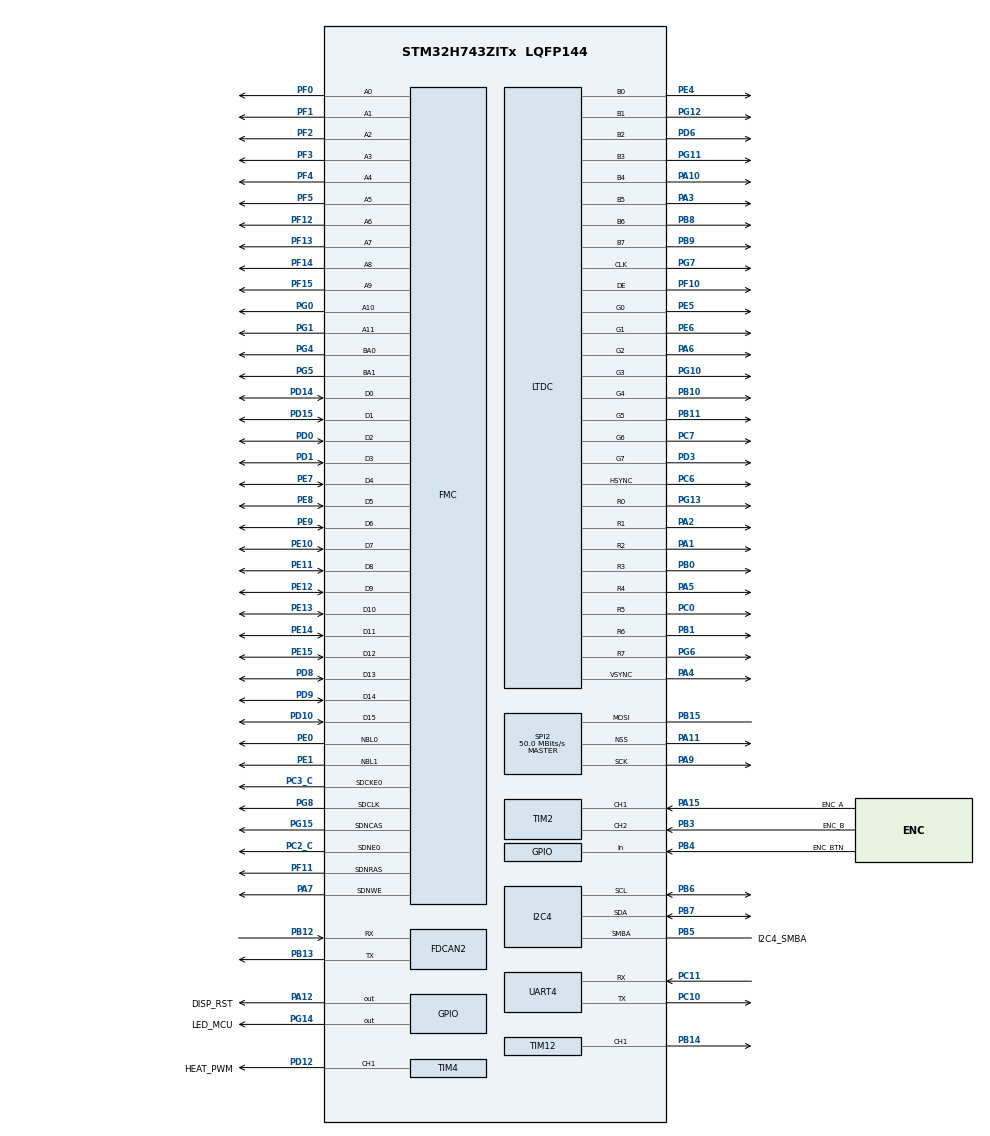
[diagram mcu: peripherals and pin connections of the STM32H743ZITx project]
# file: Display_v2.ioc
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CORTEX_M7.AccessPermission-Cortex_Memory_Protection_Unit_Region0_Settings=MPU_REGION_PRIV_RW
CORTEX_M7.AccessPermission-Cortex_Memory_Protection_Unit_Region1_Settings=MPU_REGION_PRIV_RO
CORTEX_M7.AccessPermission-Cortex_Memory_Protection_Unit_Region2_Settings=MPU_REGION_PRIV_RW
CORTEX_M7.AccessPermission-Cortex_Memory_Protection_Unit_Region3_Settings=MPU_REGION_PRIV_RW
CORTEX_M7.AccessPermission-Cortex_Memory_Protection_Unit_Region4_Settings=MPU_REGION_PRIV_RW
CORTEX_M7.AccessPermission-Cortex_Memory_Protection_Unit_Region5_Settings=MPU_REGION_PRIV_RW
CORTEX_M7.AccessPermission-Cortex_Memory_Protection_Unit_Region6_Settings=MPU_REGION_PRIV_RW
CORTEX_M7.AccessPermission-Cortex_Memory_Protection_Unit_Region7_Settings=MPU_REGION_PRIV_RW
CORTEX_M7.AccessPermission-Cortex_Memory_Protection_Unit_Region8_Settings=MPU_REGION_PRIV_RW
CORTEX_M7.BaseAddress-Cortex_Memory_Protection_Unit_Region1_Settings=0x08000000
CORTEX_M7.BaseAddress-Cortex_Memory_Protection_Unit_Region2_Settings=0x20000000
CORTEX_M7.BaseAddress-Cortex_Memory_Protection_Unit_Region3_Settings=0x24000000
CORTEX_M7.BaseAddress-Cortex_Memory_Protection_Unit_Region4_Settings=0x30000000
CORTEX_M7.BaseAddress-Cortex_Memory_Protection_Unit_Region5_Settings=0x38000000
CORTEX_M7.BaseAddress-Cortex_Memory_Protection_Unit_Region6_Settings=0x40000000
CORTEX_M7.BaseAddress-Cortex_Memory_Protection_Unit_Region7_Settings=0x60000000
CORTEX_M7.BaseAddress-Cortex_Memory_Protection_Unit_Region8_Settings=0x60000000
CORTEX_M7.CPU_DCache=Enabled
CORTEX_M7.CPU_ICache=Enabled
CORTEX_M7.DisableExec-Cortex_Memory_Protection_Unit_Region2_Settings=MPU_INSTRUCTION_ACCESS_DISABLE
CORTEX_M7.DisableExec-Cortex_Memory_Protection_Unit_Region3_Settings=MPU_INSTRUCTION_ACCESS_DISABLE
CORTEX_M7.DisableExec-Cortex_Memory_Protection_Unit_Region4_Settings=MPU_INSTRUCTION_ACCESS_DISABLE
CORTEX_M7.DisableExec-Cortex_Memory_Protection_Unit_Region5_Settings=MPU_INSTRUCTION_ACCESS_DISABLE
CORTEX_M7.DisableExec-Cortex_Memory_Protection_Unit_Region6_Settings=MPU_INSTRUCTION_ACCESS_DISABLE
CORTEX_M7.DisableExec-Cortex_Memory_Protection_Unit_Region7_Settings=MPU_INSTRUCTION_ACCESS_DISABLE
CORTEX_M7.DisableExec-Cortex_Memory_Protection_Unit_Region8_Settings=MPU_INSTRUCTION_ACCESS_DISABLE
CORTEX_M7.Enable-Cortex_Memory_Protection_Unit_Region0_Settings=MPU_REGION_ENABLE
CORTEX_M7.Enable-Cortex_Memory_Protection_Unit_Region1_Settings=MPU_REGION_ENABLE
CORTEX_M7.Enable-Cortex_Memory_Protection_Unit_Region2_Settings=MPU_REGION_ENABLE
CORTEX_M7.Enable-Cortex_Memory_Protection_Unit_Region3_Settings=MPU_REGION_ENABLE
CORTEX_M7.Enable-Cortex_Memory_Protection_Unit_Region4_Settings=MPU_REGION_ENABLE
CORTEX_M7.Enable-Cortex_Memory_Protection_Unit_Region5_Settings=MPU_REGION_ENABLE
CORTEX_M7.Enable-Cortex_Memory_Protection_Unit_Region6_Settings=MPU_REGION_ENABLE
CORTEX_M7.Enable-Cortex_Memory_Protection_Unit_Region7_Settings=MPU_REGION_ENABLE
CORTEX_M7.Enable-Cortex_Memory_Protection_Unit_Region8_Settings=MPU_REGION_ENABLE
CORTEX_M7.IsBufferable-Cortex_Memory_Protection_Unit_Region0_Settings=MPU_ACCESS_NOT_BUFFERABLE
CORTEX_M7.IsBufferable-Cortex_Memory_Protection_Unit_Region1_Settings=MPU_ACCESS_BUFFERABLE
CORTEX_M7.IsBufferable-Cortex_Memory_Protection_Unit_Region2_Settings=MPU_ACCESS_BUFFERABLE
CORTEX_M7.IsBufferable-Cortex_Memory_Protection_Unit_Region3_Settings=MPU_ACCESS_BUFFERABLE
CORTEX_M7.IsBufferable-Cortex_Memory_Protection_Unit_Region4_Settings=MPU_ACCESS_BUFFERABLE
CORTEX_M7.IsBufferable-Cortex_Memory_Protection_Unit_Region5_Settings=MPU_ACCESS_BUFFERABLE
CORTEX_M7.IsBufferable-Cortex_Memory_Protection_Unit_Region6_Settings=MPU_ACCESS_NOT_BUFFERABLE
CORTEX_M7.IsBufferable-Cortex_Memory_Protection_Unit_Region7_Settings=MPU_ACCESS_BUFFERABLE
CORTEX_M7.IsBufferable-Cortex_Memory_Protection_Unit_Region8_Settings=MPU_ACCESS_BUFFERABLE
CORTEX_M7.IsCacheable-Cortex_Memory_Protection_Unit_Region0_Settings=MPU_ACCESS_NOT_CACHEABLE
CORTEX_M7.IsCacheable-Cortex_Memory_Protection_Unit_Region1_Settings=MPU_ACCESS_CACHEABLE
CORTEX_M7.IsCacheable-Cortex_Memory_Protection_Unit_Region2_Settings=MPU_ACCESS_CACHEABLE
CORTEX_M7.IsCacheable-Cortex_Memory_Protection_Unit_Region3_Settings=MPU_ACCESS_CACHEABLE
CORTEX_M7.IsCacheable-Cortex_Memory_Protection_Unit_Region4_Settings=MPU_ACCESS_CACHEABLE
CORTEX_M7.IsCacheable-Cortex_Memory_Protection_Unit_Region5_Settings=MPU_ACCESS_CACHEABLE
CORTEX_M7.IsCacheable-Cortex_Memory_Protection_Unit_Region6_Settings=MPU_ACCESS_NOT_CACHEABLE
CORTEX_M7.IsCacheable-Cortex_Memory_Protection_Unit_Region7_Settings=MPU_ACCESS_CACHEABLE
CORTEX_M7.IsCacheable-Cortex_Memory_Protection_Unit_Region8_Settings=MPU_ACCESS_CACHEABLE
CORTEX_M7.IsShareable-Cortex_Memory_Protection_Unit_Region5_Settings=MPU_ACCESS_NOT_SHAREABLE
CORTEX_M7.IsShareable-Cortex_Memory_Protection_Unit_Region7_Settings=MPU_ACCESS_NOT_SHAREABLE
CORTEX_M7.IsShareable-Cortex_Memory_Protection_Unit_Region8_Settings=MPU_ACCESS_SHAREABLE
CORTEX_M7.MPU_Control=MPU_HARDFAULT_NMI
CORTEX_M7.Size-Cortex_Memory_Protection_Unit_Region0_Settings=MPU_REGION_SIZE_64KB
CORTEX_M7.Size-Cortex_Memory_Protection_Unit_Region1_Settings=MPU_REGION_SIZE_2MB
CORTEX_M7.Size-Cortex_Memory_Protection_Unit_Region2_Settings=MPU_REGION_SIZE_128KB
CORTEX_M7.Size-Cortex_Memory_Protection_Unit_Region3_Settings=MPU_REGION_SIZE_512KB
CORTEX_M7.Size-Cortex_Memory_Protection_Unit_Region4_Settings=MPU_REGION_SIZE_512KB
CORTEX_M7.Size-Cortex_Memory_Protection_Unit_Region5_Settings=MPU_REGION_SIZE_64KB
CORTEX_M7.Size-Cortex_Memory_Protection_Unit_Region6_Settings=MPU_REGION_SIZE_512MB
CORTEX_M7.Size-Cortex_Memory_Protection_Unit_Region7_Settings=MPU_REGION_SIZE_8MB
CORTEX_M7.Size-Cortex_Memory_Protection_Unit_Region8_Settings=MPU_REGION_SIZE_1MB
CORTEX_M7.SubRegionDisable-Cortex_Memory_Protection_Unit_Region5_Settings=0x00
CORTEX_M7.TypeExtField-Cortex_Memory_Protection_Unit_Region3_Settings=MPU_TEX_LEVEL0
CORTEX_M7.TypeExtField-Cortex_Memory_Protection_Unit_Region4_Settings=MPU_TEX_LEVEL0
CORTEX_M7.TypeExtField-Cortex_Memory_Protection_Unit_Region5_Settings=MPU_TEX_LEVEL0
CORTEX_M7.TypeExtField-Cortex_Memory_Protection_Unit_Region7_Settings=MPU_TEX_LEVEL0
CORTEX_M7.default_mode_Activation=0
FDCAN2.AutoRetransmission=DISABLE
FDCAN2.CalculateBaudRateNominal=400000
FDCAN2.CalculateTimeBitNominal=2500
FDCAN2.CalculateTimeQuantumNominal=100.0
FDCAN2.ClockCalibrationCCU=DISABLE
FDCAN2.DataPrescaler=10
FDCAN2.DataTimeSeg1=18
FDCAN2.DataTimeSeg2=6
FDCAN2.ExtFiltersNbr=12
FDCAN2.FrameFormat=FDCAN_FRAME_CLASSIC
FDCAN2.NominalPrescaler=10
FDCAN2.NominalTimeSeg1=18
FDCAN2.NominalTimeSeg2=6
FDCAN2.ProtocolException=DISABLE
FDCAN2.RxBuffersNbr=12
FDCAN2.RxFifo0ElmtsNbr=0
FDCAN2.RxFifo1ElmtsNbr=0
FDCAN2.StdFiltersNbr=0
FDCAN2.TxFifoQueueElmtsNbr=32
FMC.BankMapConfig=FMC_SWAPBMAP_SDRAM_SRAM
FMC.CASLatency1=FMC_SDRAM_CAS_LATENCY_3
FMC.ExitSelfRefreshDelay1=14
FMC.LoadToActiveDelay1=2
FMC.RCDDelay1=3
FMC.RPDelay1=3
FMC.RPDelay2=3
FMC.ReadBurst1=FMC_SDRAM_RBURST_ENABLE
FMC.ReadBurst2=FMC_SDRAM_RBURST_ENABLE
FMC.RowCycleDelay1=12
FMC.RowCycleDelay2=12
FMC.SDClockPeriod1=FMC_SDRAM_CLOCK_PERIOD_2
FMC.SDClockPeriod2=FMC_SDRAM_CLOCK_PERIOD_2
FMC.SelfRefreshTime1=8
FMC.WriteRecoveryTime1=3
I2C4.Timeout=0x000085B8
I2C4.Timing=0x307075B1
LTDC.ActiveH=240
LTDC.ActiveW=320
LTDC.Alpha0_L0=0
LTDC.Alpha0_L1=0
LTDC.Alpha_L0=255
LTDC.Blue=0
LTDC.Blue_L0=0
LTDC.DEPolarity=LTDC_DEPOLARITY_AH
LTDC.Green_L1=0
LTDC.HBP=67
LTDC.HFP=20
LTDC.HSync=2
LTDC.ImageHeight_L0=240
LTDC.ImageHeight_L1=240
LTDC.ImageWidth_L0=320
LTDC.Layers=0
LTDC.PixelFormat_L0=LTDC_PIXEL_FORMAT_RGB565
LTDC.Red=0
LTDC.Red_L0=0
LTDC.VBP=17
LTDC.VFP=4
LTDC.VSync=2
LTDC.WindowX1_L0=320
LTDC.WindowX1_L1=320
LTDC.WindowY1_L0=240
LTDC.WindowY1_L1=240
Mcu.Family=STM32H7
Mcu.Name=STM32H743ZITx
Mcu.Package=LQFP144
Mcu.UserConstants=can,$$_FDCAN2_IP_HANDLE_$$
NVIC.LTDC_IRQn=true\:0\:0\:false\:false\:true\:true\:true\:true
NVIC.PriorityGroup=NVIC_PRIORITYGROUP_4
NVIC.TIM17_IRQn=true\:15\:0\:false\:false\:true\:false\:true\:true
NVIC.TimeBase=TIM17_IRQn
NVIC.TimeBaseIP=TIM17
PA1.GPIO_Speed=GPIO_SPEED_FREQ_VERY_HIGH
PA1.Mode=RGB888
PA1.Signal=LTDC_R2
PA10.GPIO_Speed=GPIO_SPEED_FREQ_VERY_HIGH
PA10.Mode=RGB888
PA10.Signal=LTDC_B4
PA11.Mode=NSS_Signal_Hard_Output
PA11.Signal=SPI2_NSS
PA12.GPIO_Label=DISP_RST
PA12.Signal=GPIO_Output
PA13\ (JTMS/SWDIO).GPIO_Label=SWDIO
PA13\ (JTMS/SWDIO).Mode=Serial_Wire
PA13\ (JTMS/SWDIO).Signal=DEBUG_JTMS-SWDIO
PA14\ (JTCK/SWCLK).GPIO_Label=SWCLK
PA14\ (JTCK/SWCLK).Mode=Serial_Wire
PA14\ (JTCK/SWCLK).Signal=DEBUG_JTCK-SWCLK
PA15\ (JTDI).GPIO_Label=ENC_A
PA15\ (JTDI).Signal=S_TIM2_CH1_ETR
PA2.GPIO_Speed=GPIO_SPEED_FREQ_VERY_HIGH
PA2.Mode=RGB888
PA2.Signal=LTDC_R1
PA3.GPIO_Speed=GPIO_SPEED_FREQ_VERY_HIGH
PA3.Mode=RGB888
PA3.Signal=LTDC_B5
PA4.GPIO_Speed=GPIO_SPEED_FREQ_VERY_HIGH
PA4.Mode=RGB888
PA4.Signal=LTDC_VSYNC
PA5.GPIO_Speed=GPIO_SPEED_FREQ_VERY_HIGH
PA5.Mode=RGB888
PA5.Signal=LTDC_R4
PA6.GPIO_Speed=GPIO_SPEED_FREQ_VERY_HIGH
PA6.Mode=RGB888
PA6.Signal=LTDC_G2
PA7.Signal=FMC_SDNWE
PA9.Mode=Simplex_Bidirectional_Master
PA9.Signal=SPI2_SCK
PB0.GPIO_Speed=GPIO_SPEED_FREQ_VERY_HIGH
PB0.Mode=RGB888
PB0.Signal=LTDC_R3
PB1.GPIO_Speed=GPIO_SPEED_FREQ_VERY_HIGH
PB1.Mode=RGB888
PB1.Signal=LTDC_R6
PB10.GPIO_Speed=GPIO_SPEED_FREQ_VERY_HIGH
PB10.Mode=RGB888
PB10.Signal=LTDC_G4
PB11.GPIO_Speed=GPIO_SPEED_FREQ_VERY_HIGH
PB11.Mode=RGB888
PB11.Signal=LTDC_G5
PB12.Mode=FDCAN_Activate
PB12.Signal=FDCAN2_RX
PB13.Mode=FDCAN_Activate
PB13.Signal=FDCAN2_TX
PB14.Signal=S_TIM12_CH1
PB15.Mode=Simplex_Bidirectional_Master
PB15.Signal=SPI2_MOSI
PB3\ (JTDO/TRACESWO).GPIO_Label=ENC_B
PB3\ (JTDO/TRACESWO).Signal=S_TIM2_CH2
PB4\ (NJTRST).GPIO_Label=ENC_BTN
PB4\ (NJTRST).Signal=GPIO_Input
PB5.GPIO_Label=I2C4_SMBA
PB5.Mode=SMBus-Alert-mode
PB5.Signal=I2C4_SMBA
PB6.Mode=SMBus-Alert-mode
PB6.Signal=I2C4_SCL
PB7.Mode=SMBus-Alert-mode
PB7.Signal=I2C4_SDA
PB8.GPIO_Speed=GPIO_SPEED_FREQ_VERY_HIGH
PB8.Mode=RGB888
PB8.Signal=LTDC_B6
PB9.GPIO_Speed=GPIO_SPEED_FREQ_VERY_HIGH
PB9.Mode=RGB888
PB9.Signal=LTDC_B7
PC0.GPIO_Speed=GPIO_SPEED_FREQ_VERY_HIGH
PC0.Mode=RGB888
PC0.Signal=LTDC_R5
PC10.Mode=Asynchronous
PC10.Signal=UART4_TX
PC11.Mode=Asynchronous
PC11.Signal=UART4_RX
PC2_C.Mode=SdramChipSelect1_1
PC2_C.Signal=FMC_SDNE0
PC3_C.Mode=SdramChipSelect1_1
PC3_C.Signal=FMC_SDCKE0
PC6.GPIO_Speed=GPIO_SPEED_FREQ_VERY_HIGH
PC6.Mode=RGB888
PC6.Signal=LTDC_HSYNC
PC7.GPIO_Speed=GPIO_SPEED_FREQ_VERY_HIGH
PC7.Mode=RGB888
PC7.Signal=LTDC_G6
PD0.Signal=FMC_D2_DA2
PD1.Signal=FMC_D3_DA3
PD10.Signal=FMC_D15_DA15
PD12.GPIO_Label=HEAT_PWM
PD12.Signal=S_TIM4_CH1
PD14.Signal=FMC_D0_DA0
PD15.Signal=FMC_D1_DA1
PD3.GPIO_Speed=GPIO_SPEED_FREQ_VERY_HIGH
PD3.Mode=RGB888
PD3.Signal=LTDC_G7
PD6.GPIO_Speed=GPIO_SPEED_FREQ_VERY_HIGH
PD6.Mode=RGB888
PD6.Signal=LTDC_B2
PD8.Signal=FMC_D13_DA13
PD9.Signal=FMC_D14_DA14
PE0.Signal=FMC_NBL0
PE1.Signal=FMC_NBL1
PE10.Signal=FMC_D7_DA7
PE11.Signal=FMC_D8_DA8
PE12.Signal=FMC_D9_DA9
PE13.Signal=FMC_D10_DA10
PE14.Signal=FMC_D11_DA11
PE15.Signal=FMC_D12_DA12
PE4.GPIO_Speed=GPIO_SPEED_FREQ_VERY_HIGH
PE4.Mode=RGB888
PE4.Signal=LTDC_B0
PE5.GPIO_Speed=GPIO_SPEED_FREQ_VERY_HIGH
PE5.Mode=RGB888
PE5.Signal=LTDC_G0
PE6.GPIO_Speed=GPIO_SPEED_FREQ_VERY_HIGH
PE6.Mode=RGB888
PE6.Signal=LTDC_G1
PE7.Signal=FMC_D4_DA4
PE8.Signal=FMC_D5_DA5
PE9.Signal=FMC_D6_DA6
PF0.Signal=FMC_A0
PF1.Signal=FMC_A1
PF10.GPIO_Speed=GPIO_SPEED_FREQ_VERY_HIGH
PF10.Mode=RGB888
PF10.Signal=LTDC_DE
PF11.Signal=FMC_SDNRAS
PF12.Signal=FMC_A6
PF13.Signal=FMC_A7
PF14.Signal=FMC_A8
PF15.Signal=FMC_A9
PF2.Signal=FMC_A2
PF3.Signal=FMC_A3
PF4.Signal=FMC_A4
PF5.Signal=FMC_A5
PG0.Signal=FMC_A10
PG1.Signal=FMC_A11
PG10.GPIO_Speed=GPIO_SPEED_FREQ_VERY_HIGH
PG10.Mode=RGB888
PG10.Signal=LTDC_G3
PG11.GPIO_Speed=GPIO_SPEED_FREQ_VERY_HIGH
PG11.Mode=RGB888
PG11.Signal=LTDC_B3
PG12.GPIO_Speed=GPIO_SPEED_FREQ_VERY_HIGH
PG12.Mode=RGB888
PG12.Signal=LTDC_B1
PG13.GPIO_Speed=GPIO_SPEED_FREQ_VERY_HIGH
PG13.Mode=RGB888
PG13.Signal=LTDC_R0
PG14.GPIO_Label=LED_MCU
PG14.Signal=GPIO_Output
PG15.Signal=FMC_SDNCAS
PG4.Signal=FMC_A14_BA0
PG5.Signal=FMC_A15_BA1
PG6.GPIO_Speed=GPIO_SPEED_FREQ_VERY_HIGH
PG6.Mode=RGB888
PG6.Signal=LTDC_R7
PG7.GPIO_Speed=GPIO_SPEED_FREQ_VERY_HIGH
PG7.Mode=RGB888
PG7.Signal=LTDC_CLK
PG8.Signal=FMC_SDCLK
PH0-OSC_IN\ (PH0).Mode=HSE-External-Oscillator
PH0-OSC_IN\ (PH0).Signal=RCC_OSC_IN
PH1-OSC_OUT\ (PH1).Mode=HSE-External-Oscillator
PH1-OSC_OUT\ (PH1).Signal=RCC_OSC_OUT
ProjectManager.HeapSize=0x200
ProjectManager.StackSize=0x400
ProjectManager.TargetToolchain=STM32CubeIDE
RCC.ADCFreq_Value=100000000
RCC.APB1Freq_Value=120000000
RCC.APB2Freq_Value=120000000
RCC.APB3Freq_Value=120000000
RCC.APB4Freq_Value=120000000
RCC.CortexFreq_Value=480000000
RCC.D1PPRE=RCC_APB3_DIV2
RCC.D2PPRE1=RCC_APB1_DIV2
RCC.D2PPRE2=RCC_APB2_DIV2
RCC.D3PPRE=RCC_APB4_DIV2
RCC.DIVM1=8
RCC.DIVM2=8
RCC.DIVM3=8
RCC.DIVN1=480
RCC.DIVN2=200
RCC.DIVN3=100
RCC.DIVP2=4
RCC.DIVQ2=4
RCC.DIVR3=20
RCC.FDCANCLockSelection=RCC_FDCANCLKSOURCE_PLL2
RCC.FMCCLockSelection=RCC_FMCCLKSOURCE_PLL2
RCC.HCLKFreq_Value=240000000
RCC.HPRE=RCC_HCLK_DIV2
RCC.HSE_VALUE=16000000
RCC.PLLSourceVirtual=RCC_PLLSOURCE_HSE
RCC.SPI123CLockSelection=RCC_SPI123CLKSOURCE_PLL3
RCC.SYSCLKFreq_VALUE=480000000
RCC.SYSCLKSource=RCC_SYSCLKSOURCE_PLLCLK
RCC.USART234578CLockSelection=RCC_USART234578CLKSOURCE_PLL2
RCC.USBFreq_Value=480000000
SH.FMC_A0.0=FMC_A0,12b-sda1
SH.FMC_A1.0=FMC_A1,12b-sda1
SH.FMC_A10.0=FMC_A10,12b-sda1
SH.FMC_A11.0=FMC_A11,12b-sda1
SH.FMC_A14_BA0.0=FMC_BA0,FourSdramBanks1
SH.FMC_A15_BA1.0=FMC_BA1,FourSdramBanks1
SH.FMC_A2.0=FMC_A2,12b-sda1
SH.FMC_A3.0=FMC_A3,12b-sda1
SH.FMC_A4.0=FMC_A4,12b-sda1
SH.FMC_A5.0=FMC_A5,12b-sda1
SH.FMC_A6.0=FMC_A6,12b-sda1
SH.FMC_A7.0=FMC_A7,12b-sda1
SH.FMC_A8.0=FMC_A8,12b-sda1
SH.FMC_A9.0=FMC_A9,12b-sda1
SH.FMC_D0_DA0.0=FMC_D0,sd-16b-d1
SH.FMC_D10_DA10.0=FMC_D10,sd-16b-d1
SH.FMC_D11_DA11.0=FMC_D11,sd-16b-d1
SH.FMC_D12_DA12.0=FMC_D12,sd-16b-d1
SH.FMC_D13_DA13.0=FMC_D13,sd-16b-d1
SH.FMC_D14_DA14.0=FMC_D14,sd-16b-d1
SH.FMC_D15_DA15.0=FMC_D15,sd-16b-d1
SH.FMC_D1_DA1.0=FMC_D1,sd-16b-d1
SH.FMC_D2_DA2.0=FMC_D2,sd-16b-d1
SH.FMC_D3_DA3.0=FMC_D3,sd-16b-d1
SH.FMC_D4_DA4.0=FMC_D4,sd-16b-d1
SH.FMC_D5_DA5.0=FMC_D5,sd-16b-d1
SH.FMC_D6_DA6.0=FMC_D6,sd-16b-d1
SH.FMC_D7_DA7.0=FMC_D7,sd-16b-d1
SH.FMC_D8_DA8.0=FMC_D8,sd-16b-d1
SH.FMC_D9_DA9.0=FMC_D9,sd-16b-d1
SH.FMC_NBL0.0=FMC_NBL0,Sd2ByteEnable1
SH.FMC_NBL1.0=FMC_NBL1,Sd2ByteEnable1
SH.FMC_SDCLK.0=FMC_SDCLK,12b-sda1
SH.FMC_SDNCAS.0=FMC_SDNCAS,12b-sda1
SH.FMC_SDNRAS.0=FMC_SDNRAS,12b-sda1
SH.FMC_SDNWE.0=FMC_SDNWE,12b-sda1
SH.S_TIM12_CH1.0=TIM12_CH1,PWM Generation1 CH1
SH.S_TIM2_CH1_ETR.0=TIM2_CH1,Encoder_Interface
SH.S_TIM2_CH2.0=TIM2_CH2,Encoder_Interface
SH.S_TIM4_CH1.0=TIM4_CH1,PWM Generation1 CH1
SPI2.BaudRatePrescaler=SPI_BAUDRATEPRESCALER_2
SPI2.CalculateBaudRate=50.0 MBits/s
SPI2.Direction=SPI_DIRECTION_1LINE
SPI2.Mode=SPI_MODE_MASTER
SPI2.VirtualNSS=VM_NSSHARD
SPI2.VirtualType=VM_MASTER
TIM12.Channel-PWM\ Generation1\ CH1=TIM_CHANNEL_1
TIM12.Period=255
TIM12.Prescaler=19
TIM12.Pulse-PWM\ Generation1\ CH1=100
TIM4.Channel-PWM\ Generation1\ CH1=TIM_CHANNEL_1
TIM4.Period=255
TIM4.Prescaler=19
TIM4.Pulse-PWM\ Generation1\ CH1=100
VP_MEMORYMAP_VS_MEMORYMAP.Mode=CurAppReg
VP_PWR_V_PVD_IN.Mode=Mode_PVD_Int
VP_SYS_VS_tim17.Mode=TIM17
board=custom

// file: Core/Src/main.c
/* USER CODE BEGIN Header */
/**
  ******************************************************************************
  * @file           : main.c
  * @brief          : Main program body
  ******************************************************************************
  * @attention
  *
  * Copyright (c) 2025 STMicroelectronics.
  * All rights reserved.
  *
  * This software is licensed under terms that can be found in the LICENSE file
  * in the root directory of this software component.
  * If no LICENSE file comes with this software, it is provided AS-IS.
  *
  ******************************************************************************
  */
/* USER CODE END Header */
#include "main.h"
#include "fdcan.h"
#include "i2c.h"
#include "ltdc.h"
#include "memorymap.h"
#include "spi.h"
#include "tim.h"
#include "usart.h"
#include "gpio.h"
#include "fmc.h"

/* USER CODE BEGIN Includes */
#include "W9864G6KH.h"
#include "stdbool.h"
#include "app.h"
/* USER CODE END Includes */

/* USER CODE BEGIN PV */
static volatile bool sys_ready = false;
/* USER CODE END PV */

void SystemClock_Config(void);
void PeriphCommonClock_Config(void);
static void MPU_Config(void);

int main(void)
{

  /* MPU Configuration--------------------------------------------------------*/
  MPU_Config();

  /* Enable the CPU Cache */

  /* Enable I-Cache---------------------------------------------------------*/
  SCB_EnableICache();

  /* Enable D-Cache---------------------------------------------------------*/
  SCB_EnableDCache();

  /* MCU Configuration--------------------------------------------------------*/

  /* Reset of all peripherals, Initializes the Flash interface and the Systick. */
  HAL_Init();

  /* Configure the system clock */
  SystemClock_Config();

  /* Configure the peripherals common clocks */
  PeriphCommonClock_Config();

  /* Initialize all configured peripherals */
  MX_GPIO_Init();
  MX_LTDC_Init();
  MX_FMC_Init();
  MX_UART4_Init();
  MX_I2C4_SMBUS_Init();
  MX_FDCAN2_Init();
  MX_SPI2_Init();
  MX_TIM2_Init();
  MX_TIM4_Init();
  MX_TIM12_Init();
  /* USER CODE BEGIN 2 */

  HAL_GPIO_WritePin(DISP_RST_GPIO_Port, DISP_RST_Pin, GPIO_PIN_SET); // disable display's reset

  sdram_init(&hsdram1);
  sys_ready = true;
  app_run();
  /* USER CODE END 2 */

  /* Infinite loop */
  /* USER CODE BEGIN WHILE */
  __disable_irq();
  while (1)
  {
    HAL_GPIO_TogglePin(LED_MCU_GPIO_Port, LED_MCU_Pin);
    HAL_Delay(100);
    /* USER CODE END WHILE */

    /* USER CODE BEGIN 3 */
    //Error_Handler();
  }
  /* USER CODE END 3 */
}

void SystemClock_Config(void)
{
  RCC_OscInitTypeDef RCC_OscInitStruct = {0};
  RCC_ClkInitTypeDef RCC_ClkInitStruct = {0};

  /** Supply configuration update enable
  */
  HAL_PWREx_ConfigSupply(PWR_LDO_SUPPLY);

  /** Configure the main internal regulator output voltage
  */
  __HAL_PWR_VOLTAGESCALING_CONFIG(PWR_REGULATOR_VOLTAGE_SCALE0);

  while(!__HAL_PWR_GET_FLAG(PWR_FLAG_VOSRDY)) {}

  /** Initializes the RCC Oscillators according to the specified parameters
  * in the RCC_OscInitTypeDef structure.
  */
  RCC_OscInitStruct.OscillatorType = RCC_OSCILLATORTYPE_HSE;
  RCC_OscInitStruct.HSEState = RCC_HSE_ON;
  RCC_OscInitStruct.PLL.PLLState = RCC_PLL_ON;
  RCC_OscInitStruct.PLL.PLLSource = RCC_PLLSOURCE_HSE;
  RCC_OscInitStruct.PLL.PLLM = 8;
  RCC_OscInitStruct.PLL.PLLN = 480;
  RCC_OscInitStruct.PLL.PLLP = 2;
  RCC_OscInitStruct.PLL.PLLQ = 2;
  RCC_OscInitStruct.PLL.PLLR = 2;
  RCC_OscInitStruct.PLL.PLLRGE = RCC_PLL1VCIRANGE_1;
  RCC_OscInitStruct.PLL.PLLVCOSEL = RCC_PLL1VCOWIDE;
  RCC_OscInitStruct.PLL.PLLFRACN = 0;
  if (HAL_RCC_OscConfig(&RCC_OscInitStruct) != HAL_OK)
  {
    Error_Handler();
  }

  /** Initializes the CPU, AHB and APB buses clocks
  */
  RCC_ClkInitStruct.ClockType = RCC_CLOCKTYPE_HCLK|RCC_CLOCKTYPE_SYSCLK
                              |RCC_CLOCKTYPE_PCLK1|RCC_CLOCKTYPE_PCLK2
                              |RCC_CLOCKTYPE_D3PCLK1|RCC_CLOCKTYPE_D1PCLK1;
  RCC_ClkInitStruct.SYSCLKSource = RCC_SYSCLKSOURCE_PLLCLK;
  RCC_ClkInitStruct.SYSCLKDivider = RCC_SYSCLK_DIV1;
  RCC_ClkInitStruct.AHBCLKDivider = RCC_HCLK_DIV2;
  RCC_ClkInitStruct.APB3CLKDivider = RCC_APB3_DIV2;
  RCC_ClkInitStruct.APB1CLKDivider = RCC_APB1_DIV2;
  RCC_ClkInitStruct.APB2CLKDivider = RCC_APB2_DIV2;
  RCC_ClkInitStruct.APB4CLKDivider = RCC_APB4_DIV2;

  if (HAL_RCC_ClockConfig(&RCC_ClkInitStruct, FLASH_LATENCY_4) != HAL_OK)
  {
    Error_Handler();
  }
}

void PeriphCommonClock_Config(void)
{
  RCC_PeriphCLKInitTypeDef PeriphClkInitStruct = {0};

  /** Initializes the peripherals clock
  */
  PeriphClkInitStruct.PeriphClockSelection = RCC_PERIPHCLK_FMC|RCC_PERIPHCLK_SPI2
                              |RCC_PERIPHCLK_FDCAN|RCC_PERIPHCLK_UART4
                              |RCC_PERIPHCLK_LTDC;
  PeriphClkInitStruct.PLL2.PLL2M = 8;
  PeriphClkInitStruct.PLL2.PLL2N = 200;
  PeriphClkInitStruct.PLL2.PLL2P = 4;
  PeriphClkInitStruct.PLL2.PLL2Q = 4;
  PeriphClkInitStruct.PLL2.PLL2R = 2;
  PeriphClkInitStruct.PLL2.PLL2RGE = RCC_PLL2VCIRANGE_1;
  PeriphClkInitStruct.PLL2.PLL2VCOSEL = RCC_PLL2VCOWIDE;
  PeriphClkInitStruct.PLL2.PLL2FRACN = 0;
  PeriphClkInitStruct.PLL3.PLL3M = 8;
  PeriphClkInitStruct.PLL3.PLL3N = 100;
  PeriphClkInitStruct.PLL3.PLL3P = 2;
  PeriphClkInitStruct.PLL3.PLL3Q = 2;
  PeriphClkInitStruct.PLL3.PLL3R = 20;
  PeriphClkInitStruct.PLL3.PLL3RGE = RCC_PLL3VCIRANGE_1;
  PeriphClkInitStruct.PLL3.PLL3VCOSEL = RCC_PLL3VCOWIDE;
  PeriphClkInitStruct.PLL3.PLL3FRACN = 0;
  PeriphClkInitStruct.FmcClockSelection = RCC_FMCCLKSOURCE_PLL2;
  PeriphClkInitStruct.Spi123ClockSelection = RCC_SPI123CLKSOURCE_PLL3;
  PeriphClkInitStruct.FdcanClockSelection = RCC_FDCANCLKSOURCE_PLL2;
  PeriphClkInitStruct.Usart234578ClockSelection = RCC_USART234578CLKSOURCE_PLL2;
  if (HAL_RCCEx_PeriphCLKConfig(&PeriphClkInitStruct) != HAL_OK)
  {
    Error_Handler();
  }
}

 /* MPU Configuration */

void MPU_Config(void)
{
  MPU_Region_InitTypeDef MPU_InitStruct = {0};

  /* Disables the MPU */
  HAL_MPU_Disable();

  /** Initializes and configures the Region and the memory to be protected
  */
  MPU_InitStruct.Enable = MPU_REGION_ENABLE;
  MPU_InitStruct.Number = MPU_REGION_NUMBER0;
  MPU_InitStruct.BaseAddress = 0x0;
  MPU_InitStruct.Size = MPU_REGION_SIZE_64KB;
  MPU_InitStruct.SubRegionDisable = 0x0;
  MPU_InitStruct.TypeExtField = MPU_TEX_LEVEL0;
  MPU_InitStruct.AccessPermission = MPU_REGION_PRIV_RW;
  MPU_InitStruct.DisableExec = MPU_INSTRUCTION_ACCESS_ENABLE;
  MPU_InitStruct.IsShareable = MPU_ACCESS_NOT_SHAREABLE;
  MPU_InitStruct.IsCacheable = MPU_ACCESS_NOT_CACHEABLE;
  MPU_InitStruct.IsBufferable = MPU_ACCESS_NOT_BUFFERABLE;

  HAL_MPU_ConfigRegion(&MPU_InitStruct);

  /** Initializes and configures the Region and the memory to be protected
  */
  MPU_InitStruct.Number = MPU_REGION_NUMBER1;
  MPU_InitStruct.BaseAddress = 0x08000000;
  MPU_InitStruct.Size = MPU_REGION_SIZE_2MB;
  MPU_InitStruct.AccessPermission = MPU_REGION_PRIV_RO;
  MPU_InitStruct.IsCacheable = MPU_ACCESS_CACHEABLE;
  MPU_InitStruct.IsBufferable = MPU_ACCESS_BUFFERABLE;

  HAL_MPU_ConfigRegion(&MPU_InitStruct);

  /** Initializes and configures the Region and the memory to be protected
  */
  MPU_InitStruct.Number = MPU_REGION_NUMBER2;
  MPU_InitStruct.BaseAddress = 0x20000000;
  MPU_InitStruct.Size = MPU_REGION_SIZE_128KB;
  MPU_InitStruct.AccessPermission = MPU_REGION_PRIV_RW;
  MPU_InitStruct.DisableExec = MPU_INSTRUCTION_ACCESS_DISABLE;

  HAL_MPU_ConfigRegion(&MPU_InitStruct);

  /** Initializes and configures the Region and the memory to be protected
  */
  MPU_InitStruct.Number = MPU_REGION_NUMBER3;
  MPU_InitStruct.BaseAddress = 0x24000000;
  MPU_InitStruct.Size = MPU_REGION_SIZE_512KB;

  HAL_MPU_ConfigRegion(&MPU_InitStruct);

  /** Initializes and configures the Region and the memory to be protected
  */
  MPU_InitStruct.Number = MPU_REGION_NUMBER4;
  MPU_InitStruct.BaseAddress = 0x30000000;

  HAL_MPU_ConfigRegion(&MPU_InitStruct);

  /** Initializes and configures the Region and the memory to be protected
  */
  MPU_InitStruct.Number = MPU_REGION_NUMBER5;
  MPU_InitStruct.BaseAddress = 0x38000000;
  MPU_InitStruct.Size = MPU_REGION_SIZE_64KB;
  MPU_InitStruct.SubRegionDisable = 0x00;

  HAL_MPU_ConfigRegion(&MPU_InitStruct);

  /** Initializes and configures the Region and the memory to be protected
  */
  MPU_InitStruct.Number = MPU_REGION_NUMBER6;
  MPU_InitStruct.BaseAddress = 0x40000000;
  MPU_InitStruct.Size = MPU_REGION_SIZE_512MB;
  MPU_InitStruct.SubRegionDisable = 0x0;
  MPU_InitStruct.IsCacheable = MPU_ACCESS_NOT_CACHEABLE;
  MPU_InitStruct.IsBufferable = MPU_ACCESS_NOT_BUFFERABLE;

  HAL_MPU_ConfigRegion(&MPU_InitStruct);

  /** Initializes and configures the Region and the memory to be protected
  */
  MPU_InitStruct.Number = MPU_REGION_NUMBER7;
  MPU_InitStruct.BaseAddress = 0x60000000;
  MPU_InitStruct.Size = MPU_REGION_SIZE_8MB;
  MPU_InitStruct.IsCacheable = MPU_ACCESS_CACHEABLE;
  MPU_InitStruct.IsBufferable = MPU_ACCESS_BUFFERABLE;

  HAL_MPU_ConfigRegion(&MPU_InitStruct);

  /** Initializes and configures the Region and the memory to be protected
  */
  MPU_InitStruct.Number = MPU_REGION_NUMBER8;
  MPU_InitStruct.Size = MPU_REGION_SIZE_1MB;
  MPU_InitStruct.IsShareable = MPU_ACCESS_SHAREABLE;

  HAL_MPU_ConfigRegion(&MPU_InitStruct);
  /* Enables the MPU */
  HAL_MPU_Enable(MPU_HARDFAULT_NMI);

}

void HAL_TIM_PeriodElapsedCallback(TIM_HandleTypeDef *htim)
{
  if (htim->Instance == TIM17) {
    HAL_IncTick();
  }
  /* USER CODE BEGIN Callback 1 */
  if(sys_ready)
    app_on_timer();
  /* USER CODE END Callback 1 */
}

void Error_Handler(void)
{
  __disable_irq();
  while (1)
  {
  }
}
